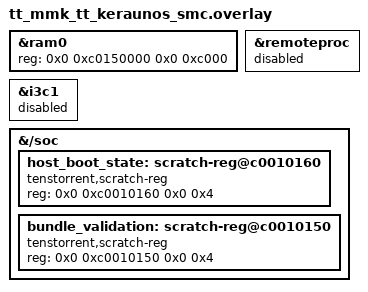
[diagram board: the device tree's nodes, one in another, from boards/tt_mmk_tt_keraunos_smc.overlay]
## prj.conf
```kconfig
# Copyright (c) 2026 Tenstorrent AI ULC
# SPDX-License-Identifier: Apache-2.0
CONFIG_I3C=n

# BL0P5 jumps to BL1 in main() and never returns; the PVT sensor
# driver and MCUboot flash-confirm logic are unused in this variant.
CONFIG_SENSOR=n
CONFIG_FLASH=n

# No float/double formatting needed in this variant's printk/printf usage
CONFIG_CBPRINTF_FP_SUPPORT=n
CONFIG_PICOLIBC_IO_LONG_LONG=n

# BUN2 loader jumps to BL1 and never returns; no interrupts are serviced and the idle
# thread is never scheduled, so their stacks can be shrunk to the bare minimum.
CONFIG_ISR_STACK_SIZE=512
CONFIG_IDLE_STACK_SIZE=256

# BL1 runs on a single CPU; eliminates 3 extra ISR stacks and idle stacks (~7.7 KB)
CONFIG_MP_MAX_NUM_CPUS=1

# Deferred logging is flushed by a thread that never gets to run before the jump to BL1,
# so messages are emitted synchronously instead.
CONFIG_LOG=y
CONFIG_LOG_MODE_IMMEDIATE=y

# Disable PMP to save padding space...
CONFIG_RISCV_PMP=n

# Tag logs with BL0.5
CONFIG_LOG_TAG_MAX_LEN=5
CONFIG_LOG_TAG_DEFAULT="BL0.5"
```

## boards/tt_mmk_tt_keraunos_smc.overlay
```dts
/*
 * Copyright (c) 2026 Tenstorrent AI ULC
 *
 * SPDX-License-Identifier: Apache-2.0
 */

/* BL0P5 starts 64KB from the end of ram0, 48KB available */
&ram0 {
	reg = <0x0 0xc0150000 0x0 0xc000>;
};

/* Not used by BUN2/BL0P5; disables the remoteproc driver and the I3C bus it depends on */
&remoteproc {
	status = "disabled";
};

&i3c1 {
	status = "disabled";
};

&{/soc} {
	host_boot_state: scratch-reg@c0010160 {
		/* SCRATCH[12] */
		compatible = "tenstorrent,scratch-reg";
		reg = <0x0 0xc0010160 0x0 0x4>;
		status = "okay";
	};

	bundle_validation: scratch-reg@c0010150 {
		/* SCRATCH[10] */
		compatible = "tenstorrent,scratch-reg";
		reg = <0x0 0xc0010150 0x0 0x4>;
		status = "okay";
	};
};
```

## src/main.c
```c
/*
 * Copyright (c) 2026 Tenstorrent AI ULC
 * SPDX-License-Identifier: Apache-2.0
 */

#include <errno.h>
#include <string.h>

#include <zephyr/devicetree.h>
#include <zephyr/drivers/misc/tt_bundle_loader.h>
#include <zephyr/sys/util.h>
#include <zephyr/kernel.h>
#include <zephyr/logging/log.h>
#include <zephyr/sys/sys_io.h>

LOG_MODULE_REGISTER(main, CONFIG_TT_APP_LOG_LEVEL);

/* Host <-> SMC boot handshake states, written/polled via the host-boot-state scratch register */
#define HOST_BOOT_STATE_WAIT_FOR_BUNDLE (1U)
#define HOST_BOOT_STATE_BUNDLE_STAGED   (2U)
#define HOST_BOOT_STATE_BUNDLE_CONSUMED (3U)

/* Bundle validation handshake bits, in the bundle-validation scratch register */
#define BUNDLE_READY_FOR_VALIDATION_BIT BIT(0)
#define BUNDLE_VALIDATED_BIT            BIT(1)

/* SMC_CPU_SMC_CPU_CTRL_RESET_VECTOR_0 local address */
#define SMC_RESET_VECTOR0_ADDR 0xC0010000UL

#define HOST_BOOT_STATE_ADDR   ((uintptr_t)DT_REG_ADDR(DT_NODELABEL(host_boot_state)))
#define BUNDLE_VALIDATION_ADDR ((uintptr_t)DT_REG_ADDR(DT_NODELABEL(bundle_validation)))

static int bl1_launcher_init(void)
{
	/* A) Tell the host we are ready to receive a bundle */
	sys_write32(HOST_BOOT_STATE_WAIT_FOR_BUNDLE, HOST_BOOT_STATE_ADDR);

	/* B) Wait for the host to stage the bundle in the staging area */
	LOG_INF("Waiting for BUN2 staging");
	while ((sys_read32(HOST_BOOT_STATE_ADDR) & 0xF) != HOST_BOOT_STATE_BUNDLE_STAGED) {
		k_busy_wait(100);
	}

	/* Close host access to the staging area; only the SMC touches it from here on */

	/* D) Request validation of the staged bundle */
	sys_write32(BUNDLE_READY_FOR_VALIDATION_BIT, BUNDLE_VALIDATION_ADDR);

	/* E) Wait for validation to complete */
	LOG_INF("Waiting for BUN2 validation");
	while (!(sys_read32(BUNDLE_VALIDATION_ADDR) & BUNDLE_VALIDATED_BIT)) {
		k_busy_wait(100);
	}

	const struct fw_bundle_manifest *manifest =
		(const struct fw_bundle_manifest *)TT_BUN2_STAGING_AREA_ADDR;
	const struct fw_bundle_toc *toc = (const struct fw_bundle_toc *)(TT_BUN2_STAGING_AREA_ADDR +
									 manifest->payload_offset);

	/* Bundles always place the K-SMC BL1 image at TOC index 0 */
	const struct fw_bundle_toc_entry *bl1_entry =
		(toc->image_count > 0) ? &toc->entries[0] : NULL;

	if (bl1_entry == NULL || bl1_entry->type != FW_BUNDLE_IMG_TYPE_SMC_BL1) {
		LOG_ERR("No SMC BL1 image found at TOC index 0 in staged bundle");
		return -ENOENT;
	}

	sys_write32(HOST_BOOT_STATE_BUNDLE_CONSUMED, HOST_BOOT_STATE_ADDR);

	/* F) Copy SMC BL1 from the staged bundle to its execute location */
	memcpy((void *)bl1_entry->load_addr,
	       (const void *)(TT_BUN2_STAGING_AREA_ADDR + manifest->payload_offset +
			      bl1_entry->offset),
	       bl1_entry->length);

	__asm__ volatile("fence\nfence.i" ::: "memory");

	LOG_INF("Jumping to SMC BL1 at load_addr %p", (void *)(uintptr_t)bl1_entry->load_addr);

	/* G) Jump to SMC BL1. Does not return; BL1 owns the core from here on. */
	/* mret gives BL1 a clean entry: M-mode, MIE=0, no BL0P5 mtvec leaking through */
	sys_write64(bl1_entry->entry_point, SMC_RESET_VECTOR0_ADDR);
	__asm__ volatile("csrw mepc, %0\n"
			 "li   t0, 0x1800\n" /* MPP=M-mode, MIE=0, MPIE=0 */
			 "csrw mstatus, t0\n"
			 "mret\n"
			 :
			 : "r"((uintptr_t)bl1_entry->entry_point)
			 : "t0");

	return 0;
}

int main(void)
{
	bl1_launcher_init();

	/* Unreachable unless BL1 returns, which means the handoff failed and the core's
	 * state (stack, vector table, PMP, ...) can no longer be trusted.
	 */
	k_panic();
	return 0;
}
```
